# cmsdk_ahb_gpio: IP-XACT component
VLNV arm.com:CoreLink:cmsdk_ahb_gpio:r1p0_1
AHB GPIO

## Parameters
ALTERNATE_FUNC_MASK = 65535 — Alternate function bit mask. Indicates which ports can have an alternate function instead of GPIO logic. Default 16'hFFFF so all ports can have alternate functions
ALTERNATE_FUNC_DEFAULT = 0 — Alternate function default value. Indicates which ports are used with alternate function. Default 16'h0000 so all pins are used as GPIO
BE = 0 — Big-endian (1) or little-endian (0)

## Bus interfaces (logical=physical port)
AHBLiteTarget_SLAVE: slave amba.com:AMBA3:AHBLiteTarget:r2p0_0, memory map AHBLiteTarget_SLAVE_MM — AHB SLAVE bus interface for port
  HCLK=HCLK, HRESETn=HRESETn, HADDR=HADDR, HSIZE=HSIZE, HTRANS=HTRANS, HWDATA=HWDATA, HWRITE=HWRITE, HRDATA=HRDATA, HREADYOUT=HREADYOUT, HRESP=HRESP, HREADY=HREADY, HSELx=HSEL, HBURST=HBURST
Staticcfg_ECOrevnum_Slave: slave arm.com:generic:Staticcfg:r0p0_0 — ECO Revision tie-off. Configures the ECO revision number in Peripheral ID register Register 3 to show revision changes during ECO of the chip design process.
  CONFIGURATION=ECOREVNUM
GPIO_Port_in_Slave: slave arm.com:generic:GPIO:r0p0_0 — GPIO input
  CLK=FCLK, RESETn=HRESETn, GPIO_PORT=PORTIN
GPIO_Port_out_Master: master arm.com:generic:GPIO:r0p0_0 — GPIO output
  CLK=FCLK, RESETn=HRESETn, GPIO_PORT=PORTOUT
GPIO_Port_en_Master: master arm.com:generic:GPIO:r0p0_0 — GPIO enable
  CLK=FCLK, RESETn=HRESETn, GPIO_PORT=PORTEN
GPIO_Port_func_Master: master arm.com:generic:GPIO:r0p0_0 — GPIO alternate function
  CLK=FCLK, RESETn=HRESETn, GPIO_PORT=PORTFUNC
interrupt_COMBINT_Master: master arm.com:generic:interrupt:r0p0_0 — Combined GPIO interrupt
  IRQ=COMBINT, CLK=FCLK
interrupt_GPIOINT_0_Master: master arm.com:generic:interrupt:r0p0_0 — GPIO Port 0 interrupt
  IRQ=GPIOINT[0:0], CLK=FCLK
interrupt_GPIOINT_1_Master: master arm.com:generic:interrupt:r0p0_0 — GPIO Port 1 interrupt
  IRQ=GPIOINT[1:1], CLK=FCLK
interrupt_GPIOINT_2_Master: master arm.com:generic:interrupt:r0p0_0 — GPIO Port 2 interrupt
  IRQ=GPIOINT[2:2], CLK=FCLK
interrupt_GPIOINT_3_Master: master arm.com:generic:interrupt:r0p0_0 — GPIO Port 3 interrupt
  IRQ=GPIOINT[3:3], CLK=FCLK
interrupt_GPIOINT_4_Master: master arm.com:generic:interrupt:r0p0_0 — GPIO Port 4 interrupt
  IRQ=GPIOINT[4:4], CLK=FCLK
interrupt_GPIOINT_5_Master: master arm.com:generic:interrupt:r0p0_0 — GPIO Port 5 interrupt
  IRQ=GPIOINT[5:5], CLK=FCLK
interrupt_GPIOINT_6_Master: master arm.com:generic:interrupt:r0p0_0 — GPIO Port 6 interrupt
  IRQ=GPIOINT[6:6], CLK=FCLK
interrupt_GPIOINT_7_Master: master arm.com:generic:interrupt:r0p0_0 — GPIO Port 7 interrupt
  IRQ=GPIOINT[7:7], CLK=FCLK
interrupt_GPIOINT_8_Master: master arm.com:generic:interrupt:r0p0_0 — GPIO Port 8 interrupt
  IRQ=GPIOINT[8:8], CLK=FCLK
interrupt_GPIOINT_9_Master: master arm.com:generic:interrupt:r0p0_0 — GPIO Port 9 interrupt
  IRQ=GPIOINT[9:9], CLK=FCLK
interrupt_GPIOINT_10_Master: master arm.com:generic:interrupt:r0p0_0 — GPIO Port 10 interrupt
  IRQ=GPIOINT[10:10], CLK=FCLK
interrupt_GPIOINT_11_Master: master arm.com:generic:interrupt:r0p0_0 — GPIO Port 11 interrupt
  IRQ=GPIOINT[11:11], CLK=FCLK
interrupt_GPIOINT_12_Master: master arm.com:generic:interrupt:r0p0_0 — GPIO Port 12 interrupt
  IRQ=GPIOINT[12:12], CLK=FCLK
interrupt_GPIOINT_13_Master: master arm.com:generic:interrupt:r0p0_0 — GPIO Port 13 interrupt
  IRQ=GPIOINT[13:13], CLK=FCLK
interrupt_GPIOINT_14_Master: master arm.com:generic:interrupt:r0p0_0 — GPIO Port 14 interrupt
  IRQ=GPIOINT[14:14], CLK=FCLK
interrupt_GPIOINT_15_Master: master arm.com:generic:interrupt:r0p0_0 — GPIO Port 15 interrupt
  IRQ=GPIOINT[15:15], CLK=FCLK

## Ports
in HCLK — system bus clock
in HRESETn — system bus reset
in FCLK — system bus clock
in HSEL — AHB peripheral select
in HREADY — AHB ready input
in HTRANS[1:0] — AHB transfer type
in HSIZE[2:0] — AHB hsize
in HWRITE — AHB hwrite
in HADDR[11:0] — AHB address bus
in HWDATA[31:0] — AHB write data bus
in ECOREVNUM[3:0] — Engineering-change-order revision bits
in PORTIN[15:0] — GPIO Interface input
out HREADYOUT — AHB ready output to S->M mux
out HRESP — AHB response
out HRDATA[31:0]
out PORTOUT[15:0] — GPIO output
out PORTEN[15:0] — GPIO output enable
out PORTFUNC[15:0] — Alternate function control
out GPIOINT[15:0] — Interrupt output for each pin
out COMBINT — Combined interrupt
phantom HBURST

## Address spaces and blocks
AHBLiteTarget_SLAVE_MM.cmsdk_ahb_gpio_Register_AddressBlock: base 0x0, range 4124, width 32, register

## Registers
Registers are 32-bit, read-write, reset 0x0 unless marked. A register's access mark holds for its fields unless they carry their own. Offsets are from the block's base; lines under a group give offsets from that group; [hi:lo] are bit positions; {n}, {i} and the like mark numbered series; 'fields as' and 'values as' point back to an identical list; <NAME> marks a mode.

## AHBLiteTarget_SLAVE_MM.cmsdk_ahb_gpio_Register_AddressBlock
Base 0x00000000
0x00 DATA — Data value
  [15:0] read_data ro — Sampled at pin. Read back value goes through double flip-flop
  [15:0] write_data wo — To data output register
0x04 DATOUT — Data output register value
  [15:0] read_data ro — Current value of data output register
  [15:0] write_data wo — To data output register.
0x10 OUTENSET — Output enable set
  [15:0] output_enable — Set output enables
0x14 OUTENCLR — Output enable clear
  [15:0] output_enable_clear — Clear output enables
0x18 ALTFUNCSET — Alternative function set
  [15:0] alternate_function_set — Set alternative functions
0x1C ALTFUNCCLR — Alternative function clear
  [15:0] alternate_function_clear — Clear alternative functions
0x20 INTENSET — Interrupt enable set
  [15:0] interrupt_enable — Enable interrupts
0x24 INTENCLR — Interrupt enable clear
  [15:0] interrupt_enable_clear — Clear interrupts
0x28 INTTYPESET — Interrupt type set
  [15:0] set_irq_type — Set interrupt types
0x2C INTTYPECLR — Interrupt type clear
  [15:0] clear_irq_type — Clear interrupt types
0x30 INTPOLSET — Polarity-level, edge IRQ configuration
  [15:0] set_irq_polarity_level — Set interrupt polarity levels
0x34 INTPOLCLR — Polarity-level, edge IRQ configuration clear
  [15:0] clear_irq_polarity_level — Clear interrupt polarity levels
0x38 INTSTATUS — Interrupt status/clear register
  [15:0] read_irq_status — Interrup Status
{0x400+4i} MASKLOWBYTE[{i}] (i=0..255) — Lower eight bits masked access. Bits[9:2] of the
  [7:0] lower_enable_mask
{0x800+4i} MASKHIGHBYTE[{i}] (i=0..255) — Higher eight bits masked access. Bits[9:2] of the
  [15:8] higher_enable_mask
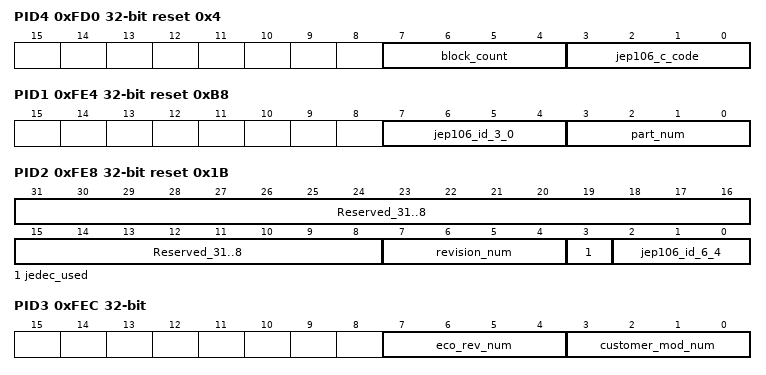
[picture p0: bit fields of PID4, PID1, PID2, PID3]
0xFD0 PID4 ro reset 0x4 — Peripheral ID Register 4
  [7:4] block_count — 4KB block count
  [3:0] jep106_c_code
{0xFC0+4i} PID{i} ro (i=5..7) — Peripheral ID Register {i}
  [7:0] PID{i}
0xFE0 PID0 ro reset 0x21 — Peripheral ID Register 0
  [7:0] part_num — Part number[7:0]
0xFE4 PID1 ro reset 0xB8 — Peripheral ID Register 1
  [7:4] jep106_id_3_0
  [3:0] part_num — Part number[11:8]
0xFE8 PID2 ro reset 0x1B — Peripheral ID Register 2
  [31:8] Reserved_31..8 — Reserved
  [7:4] revision_num — Revision
  [3] jedec_used
  [2:0] jep106_id_6_4
0xFEC PID3 ro — Peripheral ID Register 3
  [7:4] eco_rev_num — ECO revision number
  [3:0] customer_mod_num — Customer Modification Number
0xFF0 CID0 ro reset 0xD — Component ID Register 0
  [7:0] CID0
0xFF4 CID1 ro reset 0xF0 — Component ID Register 1
  [7:0] CID1
0xFF8 CID2 ro reset 0x5 — Component ID Register 2
  [7:0] CID2
0xFFC CID3 ro reset 0xB1 — Component ID Register 3
  [7:0] CID3

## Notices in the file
The confidential and proprietary information contained in this file may
only be used by a person authorised under and to the extent permitted
by a subsisting licensing agreement from ARM Limited or its affiliates.
(C) COPYRIGHT 2017 ARM Limited or its affiliates.
ALL RIGHTS RESERVED
This entire notice must be reproduced on all copies of this file
and copies of this file may only be made by a person if such person is
permitted to do so under the terms of a subsisting license agreement
from ARM Limited or its affiliates.
